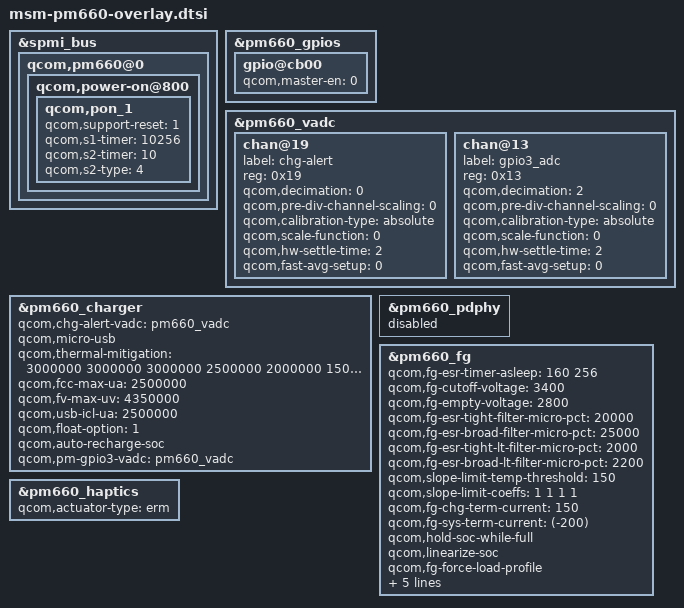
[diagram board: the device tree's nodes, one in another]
/* SPDX-License-Identifier: GPL-2.0 */

&spmi_bus {
	qcom,pm660@0 {
		qcom,power-on@800 {
			qcom,pon_1 {
				qcom,support-reset = <1>;
				qcom,s1-timer = <10256>;
				qcom,s2-timer = <10>;
				qcom,s2-type = <4>;
			};
		};
	};
};

&pm660_gpios {
	gpio@cb00 {
		status = "ok";
		qcom,master-en = <0>;
	};
};

&pm660_vadc {
	chan@19 {
		label = "chg-alert";
		reg = <0x19>;
		qcom,decimation = <0>;
		qcom,pre-div-channel-scaling = <0>;
		qcom,calibration-type = "absolute";
		qcom,scale-function = <0>;
		qcom,hw-settle-time = <2>;
		qcom,fast-avg-setup = <0>;
	};

	chan@13 {
		label = "gpio3_adc";
		reg = <0x13>;
		qcom,decimation = <2>;
		qcom,pre-div-channel-scaling = <0>;
		qcom,calibration-type = "absolute";
		qcom,scale-function = <0>;
		qcom,hw-settle-time = <2>;
		qcom,fast-avg-setup = <0>;
	};
};

&pm660_charger {
	qcom,chg-alert-vadc = <&pm660_vadc>;
	qcom,micro-usb;
        qcom,thermal-mitigation = <3000000 3000000 3000000 2500000 2000000 1500000>;
	qcom,fcc-max-ua = <2500000>;
	qcom,fv-max-uv = <4350000>;
	qcom,usb-icl-ua = <2500000>;
	qcom,float-option = <1>;
	qcom,auto-recharge-soc;
	qcom,pm-gpio3-vadc = <&pm660_vadc>;	
};

&pm660_pdphy {
	status = "disabled";
};

&pm660_fg {
	qcom,fg-esr-timer-asleep = <160 256>;
	qcom,fg-cutoff-voltage = <3400>;
	qcom,fg-empty-voltage = <2800>;
	qcom,fg-esr-tight-filter-micro-pct = <20000>;
	qcom,fg-esr-broad-filter-micro-pct = <25000>;
	qcom,fg-esr-tight-lt-filter-micro-pct = <2000>;
	qcom,fg-esr-broad-lt-filter-micro-pct = <2200>;
	qcom,slope-limit-temp-threshold = <150>;
	qcom,slope-limit-coeffs = <1 1 1 1>;
	qcom,fg-chg-term-current = <150>;
	qcom,fg-sys-term-current = <(-200)>;
	qcom,hold-soc-while-full;
	qcom,linearize-soc;
	qcom,fg-force-load-profile;
	qcom,fg-jeita-hyst-temp = <3>;
	qcom,fg-recharge-voltage = <4150>;
	qcom,fg-recharge-soc-thr = <98>;
	qcom,fg-auto-recharge-soc;
	qcom,fg-rsense-sel=<1>;
};

&pm660_haptics {
	qcom,actuator-type = "erm";
};
